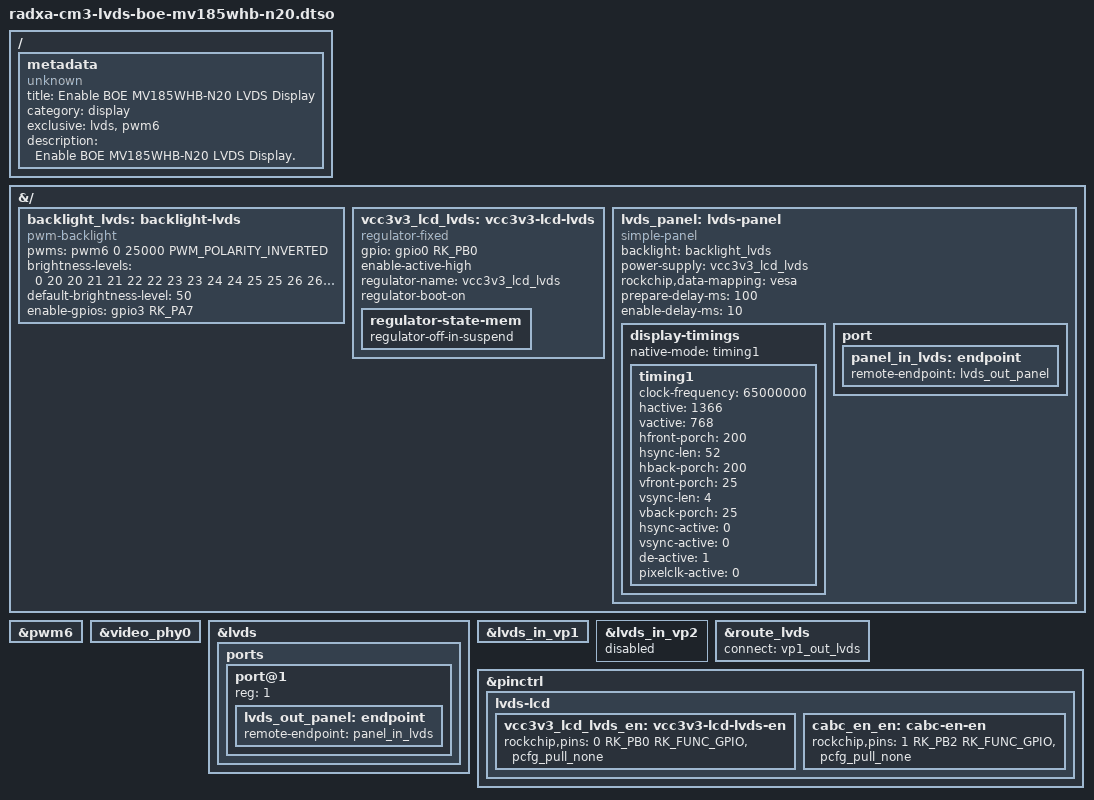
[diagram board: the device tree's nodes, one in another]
/dts-v1/;
/plugin/;

#include <dt-bindings/gpio/gpio.h>
#include <dt-bindings/pinctrl/rockchip.h>
#include <dt-bindings/pwm/pwm.h>

/ {
	metadata {
		title = "Enable BOE MV185WHB-N20 LVDS Display";
		compatible = "unknown";
		category = "display";
		exclusive = "lvds", "pwm6";
		description = "Enable BOE MV185WHB-N20 LVDS Display.";
	};
};

&{/} {
	backlight_lvds: backlight-lvds {
		status = "okay";
		compatible = "pwm-backlight";
		pwms = <&pwm6 0 25000 PWM_POLARITY_INVERTED>;
		brightness-levels = <
			0  20  20  21  21  22  22  23
			23  24  24  25  25  26  26  27
			27  28  28  29  29  30  30  31
			31  32  32  33  33  34  34  35
			35  36  36  37  37  38  38  39
			40  41  42  43  44  45  46  47
			48  49  50  51  52  53  54  55
			56  57  58  59  60  61  62  63
			64  65  66  67  68  69  70  71
			72  73  74  75  76  77  78  79
			80  81  82  83  84  85  86  87
			88  89  90  91  92  93  94  95
			96  97  98  99 100 101 102 103
			104 105 106 107 108 109 110 111
			112 113 114 115 116 117 118 119
			120 121 122 123 124 125 126 127
			128 129 130 131 132 133 134 135
			136 137 138 139 140 141 142 143
			144 145 146 147 148 149 150 151
			152 153 154 155 156 157 158 159
			160 161 162 163 164 165 166 167
			168 169 170 171 172 173 174 175
			176 177 178 179 180 181 182 183
			184 185 186 187 188 189 190 191
			192 193 194 195 196 197 198 199
			200 201 202 203 204 205 206 207
			208 209 210 211 212 213 214 215
			216 217 218 219 220 221 222 223
			224 225 226 227 228 229 230 231
			232 233 234 235 236 237 238 239
			240 241 242 243 244 245 246 247
			248 249 250 251 252 253 254 255
		>;
		default-brightness-level = <50>;
		enable-gpios = <&gpio3 RK_PA7 GPIO_ACTIVE_HIGH>;
	};

	vcc3v3_lcd_lvds: vcc3v3-lcd-lvds {
		status = "okay";
		compatible = "regulator-fixed";
		gpio = <&gpio0 RK_PB0 GPIO_ACTIVE_HIGH>;
		enable-active-high;
		regulator-name = "vcc3v3_lcd_lvds";
		regulator-boot-on;
		regulator-state-mem {
			regulator-off-in-suspend;
		};
	};

	lvds_panel: lvds-panel {
		status = "okay";
		compatible = "simple-panel";
		backlight = <&backlight_lvds>;
		power-supply = <&vcc3v3_lcd_lvds>;
		pinctrl-names = "default";
		rockchip,data-mapping = "vesa"; // LVDS Data Format
		prepare-delay-ms = <100>;
		enable-delay-ms = <10>;
		display-timings {
			native-mode = <&timing1>;
			timing1: timing1 {
				clock-frequency = <65000000>;
				hactive = <1366>;
				vactive = <768>;
				hfront-porch = <200>;
				hsync-len = <52>;
				hback-porch = <200>;
				vfront-porch = <25>;
				vsync-len = <4>;
				vback-porch = <25>;
				hsync-active = <0>;
				vsync-active = <0>;
				de-active = <1>;
				pixelclk-active = <0>;
			};
		};

		port {
			panel_in_lvds: endpoint {
					remote-endpoint = <&lvds_out_panel>;
			};
		};
	};
};

&pwm6 {
	status = "okay";
};

&video_phy0 {
	status = "okay";
};

&lvds {
	status = "okay";

	ports {
		#address-cells = <1>;
		#size-cells = <0>;
		port@1 {
			reg = <1>;

			lvds_out_panel: endpoint {
				remote-endpoint = <&panel_in_lvds>;
			};
		};
	};
};


&lvds_in_vp1 {
	status = "okay";
};

&lvds_in_vp2 {
	status = "disabled";
};

&route_lvds {
	status = "okay";
	connect = <&vp1_out_lvds>;
};

&pinctrl {
	lvds-lcd {
		vcc3v3_lcd_lvds_en: vcc3v3-lcd-lvds-en {
			rockchip,pins = <0 RK_PB0 RK_FUNC_GPIO &pcfg_pull_none>;
		};

		cabc_en_en: cabc-en-en {
			rockchip,pins = <1 RK_PB2 RK_FUNC_GPIO &pcfg_pull_none>;
		};
	};
};
